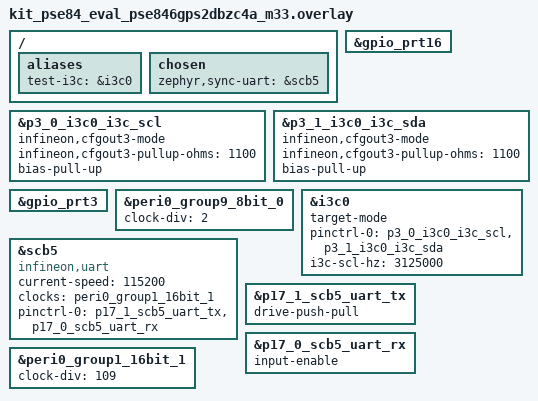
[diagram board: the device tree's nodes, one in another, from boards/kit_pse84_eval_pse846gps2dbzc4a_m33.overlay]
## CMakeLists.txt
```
# SPDX-FileCopyrightText: Copyright (c) 2026 Infineon Technologies AG,
# SPDX-FileCopyrightText: or an affiliate of Infineon Technologies AG. All rights reserved.
#
# SPDX-License-Identifier: Apache-2.0

cmake_minimum_required(VERSION 3.20.0)
find_package(Zephyr REQUIRED HINTS $ENV{ZEPHYR_BASE})
project(target_driven_target)

file(GLOB app_sources CONFIGURE_DEPENDS src/*.c)
target_sources(app PRIVATE ${app_sources})

target_include_directories(app PRIVATE ${CMAKE_CURRENT_SOURCE_DIR}/../../common)
```

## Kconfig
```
# SPDX-FileCopyrightText: Copyright (c) 2026 Infineon Technologies AG,
# SPDX-FileCopyrightText: or an affiliate of Infineon Technologies AG. All rights reserved.
#
# SPDX-License-Identifier: Apache-2.0

mainmenu "I3C loopback test (target)"

source "Kconfig.zephyr"

menu "I3C loopback target bench options"

config I3C_DUAL_BOARD_LOOPBACK_TARGET_VENDOR_WRAPPER_GATE
	bool "Re-open vendor clock-gate register during SOFT_RST"
	help
	  Some DW I3C IP integrations gate the protocol clock through a
	  vendor wrapper register that must be re-opened before SOFT_RST
	  can self-clear.  Enable this option for those integrations and
	  set the wrapper register offset and write value below.

if I3C_DUAL_BOARD_LOOPBACK_TARGET_VENDOR_WRAPPER_GATE

config I3C_DUAL_BOARD_LOOPBACK_TARGET_WRAPPER_GATE_OFFSET
	hex "Vendor wrapper-gate register offset from controller base"
	default 0x400

config I3C_DUAL_BOARD_LOOPBACK_TARGET_WRAPPER_GATE_VALUE
	hex "Value to write to the wrapper-gate register"
	default 0x80000000

endif

config I3C_DUAL_BOARD_LOOPBACK_TARGET_SOFT_RST_CLEARS_DEVICE_ADDR
	bool "DW SOFT_RST already clears DEVICE_ADDR (default true)"
	default y
	help
	  On most DW I3C variants, SOFT_RST also clears the DEVICE_ADDR
	  register.  Disable this option for variants where the stale
	  dynamic address from a previous ENTDAA round survives SOFT_RST
	  — the target side will then explicitly zero DEVICE_ADDR after
	  the reset to avoid the target believing it already has a DA
	  during the next enumeration round.

config I3C_DUAL_BOARD_LOOPBACK_TARGET_ALT_ADDR
	hex "Spare dynamic address for the address-change cases"
	default 0x40
	range 0x08 0x7d
	help
	  Address the SETNEWDA and SETDASA cases move the target to, and
	  then prove carries traffic.  Nothing else on the bus may answer
	  to it: it has to differ from the target's own static address,
	  from the controller's primary-controller-da, and from any
	  target sharing the bus.  Override it per board where the
	  default is taken.
endmenu
```

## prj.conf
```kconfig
# SPDX-FileCopyrightText: Copyright (c) 2026 Infineon Technologies AG,
# SPDX-FileCopyrightText: or an affiliate of Infineon Technologies AG. All rights reserved.
#
# SPDX-License-Identifier: Apache-2.0
#
# Target app for the target_driven two-board test pair.  Unlike the
# controller_driven pair, this side runs the ZTEST suite: it asserts on
# target-side state the controller cannot observe.

CONFIG_ZTEST=y
CONFIG_ZTEST_STACK_SIZE=4096

CONFIG_PRINTK_SYNC=y
CONFIG_FAULT_DUMP=2
CONFIG_LOG=y
CONFIG_ASSERT=y

# I3C: target-only build so the controller paths cannot mask a target bug
CONFIG_I3C=y
CONFIG_I3C_TARGET_ROLE_ONLY=y
CONFIG_I3C_USE_IBI=y

# Sync UART (poll-mode only - do not enable CONFIG_UART_INTERRUPT_DRIVEN;
# on this bench the UART IRQ handler races poll_in/poll_out and wedges
# subsequent I3C traffic.)
CONFIG_SERIAL=y

# Misc
CONFIG_PINCTRL_KEEP_SLEEP_STATE=y
CONFIG_HEAP_MEM_POOL_SIZE=4096
CONFIG_MAIN_STACK_SIZE=4096
CONFIG_CLOCK_CONTROL=y
```

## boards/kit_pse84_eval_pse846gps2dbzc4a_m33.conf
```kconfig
# SPDX-FileCopyrightText: Copyright (c) 2026 Infineon Technologies AG,
# SPDX-FileCopyrightText: or an affiliate of Infineon Technologies AG. All rights reserved.
#
# SPDX-License-Identifier: Apache-2.0
#
# Bench configuration for KIT_PSE84_EVAL (PSE846GPS2DBZC4A, M33 core).
#
# The Infineon DW I3C wrapper on PSE84 silicon has an integration
# quirk: a vendor wrapper-gate register at base+0x400 must be
# re-opened for SOFT_RST to self-clear, because the protocol clock
# is gated by it.
CONFIG_I3C_DUAL_BOARD_LOOPBACK_TARGET_VENDOR_WRAPPER_GATE=y
CONFIG_I3C_DUAL_BOARD_LOOPBACK_TARGET_WRAPPER_GATE_OFFSET=0x400
CONFIG_I3C_DUAL_BOARD_LOOPBACK_TARGET_WRAPPER_GATE_VALUE=0x80000000

# On PSE84 silicon, SOFT_RST does NOT clear DEVICE_ADDR - the stale
# dynamic address from the previous ENTDAA round survives and breaks
# re-enumeration.  Disable so the target zeros DEVICE_ADDR explicitly.
CONFIG_I3C_DUAL_BOARD_LOOPBACK_TARGET_SOFT_RST_CLEARS_DEVICE_ADDR=n

# Spare address for the SETNEWDA/SETDASA cases: free on this bench,
# below the on-board sensors and above the controller's own DA.
CONFIG_I3C_DUAL_BOARD_LOOPBACK_TARGET_ALT_ADDR=0x40
```

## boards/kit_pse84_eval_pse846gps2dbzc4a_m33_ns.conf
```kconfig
# SPDX-FileCopyrightText: Copyright (c) 2026 Infineon Technologies AG,
# SPDX-FileCopyrightText: or an affiliate of Infineon Technologies AG. All rights reserved.
#
# SPDX-License-Identifier: Apache-2.0
#
# Bench configuration for KIT_PSE84_EVAL (PSE846GPS2DBZC4A, M33 non-secure
# core, TF-M).
#
# The Infineon DW I3C wrapper on PSE84 silicon has an integration
# quirk: a vendor wrapper-gate register at base+0x400 must be
# re-opened for SOFT_RST to self-clear, because the protocol clock
# is gated by it.
CONFIG_I3C_DUAL_BOARD_LOOPBACK_TARGET_VENDOR_WRAPPER_GATE=y
CONFIG_I3C_DUAL_BOARD_LOOPBACK_TARGET_WRAPPER_GATE_OFFSET=0x400
CONFIG_I3C_DUAL_BOARD_LOOPBACK_TARGET_WRAPPER_GATE_VALUE=0x80000000

# On PSE84 silicon, SOFT_RST does NOT clear DEVICE_ADDR - the stale
# dynamic address from the previous ENTDAA round survives and breaks
# re-enumeration.  Disable so the target zeros DEVICE_ADDR explicitly.
CONFIG_I3C_DUAL_BOARD_LOOPBACK_TARGET_SOFT_RST_CLEARS_DEVICE_ADDR=n

# Spare address for the SETNEWDA/SETDASA cases: free on this bench,
# below the on-board sensors and above the controller's own DA.
CONFIG_I3C_DUAL_BOARD_LOOPBACK_TARGET_ALT_ADDR=0x40
```

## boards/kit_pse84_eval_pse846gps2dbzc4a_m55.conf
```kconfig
# SPDX-FileCopyrightText: Copyright (c) 2026 Infineon Technologies AG,
# SPDX-FileCopyrightText: or an affiliate of Infineon Technologies AG. All rights reserved.
#
# SPDX-License-Identifier: Apache-2.0
#
# Bench configuration for KIT_PSE84_EVAL (PSE846GPS2DBZC4A, M55 core).
#
# The Infineon DW I3C wrapper on PSE84 silicon has an integration
# quirk: a vendor wrapper-gate register at base+0x400 must be
# re-opened for SOFT_RST to self-clear, because the protocol clock
# is gated by it.
CONFIG_I3C_DUAL_BOARD_LOOPBACK_TARGET_VENDOR_WRAPPER_GATE=y
CONFIG_I3C_DUAL_BOARD_LOOPBACK_TARGET_WRAPPER_GATE_OFFSET=0x400
CONFIG_I3C_DUAL_BOARD_LOOPBACK_TARGET_WRAPPER_GATE_VALUE=0x80000000

# On PSE84 silicon, SOFT_RST does NOT clear DEVICE_ADDR - the stale
# dynamic address from the previous ENTDAA round survives and breaks
# re-enumeration.  Disable so the target zeros DEVICE_ADDR explicitly.
CONFIG_I3C_DUAL_BOARD_LOOPBACK_TARGET_SOFT_RST_CLEARS_DEVICE_ADDR=n

# Spare address for the SETNEWDA/SETDASA cases: free on this bench,
# below the on-board sensors and above the controller's own DA.
CONFIG_I3C_DUAL_BOARD_LOOPBACK_TARGET_ALT_ADDR=0x40
```

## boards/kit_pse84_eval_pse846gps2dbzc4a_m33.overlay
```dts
/*
 * SPDX-FileCopyrightText: Copyright (c) 2026 Infineon Technologies AG,
 * SPDX-FileCopyrightText: or an affiliate of Infineon Technologies AG. All rights reserved.
 *
 * SPDX-License-Identifier: Apache-2.0
 *
 * Board overlay for the dual_board_loopback TARGET (Board B) on
 * KIT_PSE84_EVAL (M33 core).
 *
 * Wiring:
 *   B.I3C0_SCL - shared with A.I3C0_SCL    (P3.0)
 *   B.I3C0_SDA - shared with A.I3C0_SDA    (P3.1)
 *   B.SCB5 RX/TX - crossed with A.SCB5 TX/RX           (P17.0/P17.1)
 *   B.GREEN LED   - LA channel 2 (target-IP-saw-address marker, P16.6)
 */

#include <zephyr/dt-bindings/gpio/gpio.h>

/ {
	aliases {
		test-i3c = &i3c0;
	};

	chosen {
		zephyr,sync-uart = &scb5;
	};
};

&gpio_prt16 {
	status = "okay";
};

&p3_0_i3c0_i3c_scl {
	infineon,cfgout3-mode;
	infineon,cfgout3-pullup-ohms = <1100>;
	bias-pull-up;
};

&p3_1_i3c0_i3c_sda {
	infineon,cfgout3-mode;
	infineon,cfgout3-pullup-ohms = <1100>;
	bias-pull-up;
};

&gpio_prt3 {
	status = "okay";
};

/* Match the controller overlay: the target samples SCL with this clock. */
&peri0_group9_8bit_0 {
	status = "okay";
	clock-div = <2>;
};

&i3c0 {
	status = "okay";
	target-mode;
	pinctrl-0 = <&p3_0_i3c0_i3c_scl &p3_1_i3c0_i3c_sda>;
	pinctrl-names = "default";
	i3c-scl-hz = <3125000>;

	/* Target PID/BCR/DCR are set at runtime; see common/test_identity.h. */
};

scb5_sync_uart: &scb5 {
	compatible = "infineon,uart";
	status = "okay";
	current-speed = <115200>;
	clocks = <&peri0_group1_16bit_1>;
	pinctrl-0 = <&p17_1_scb5_uart_tx &p17_0_scb5_uart_rx>;
	pinctrl-names = "default";
};

&p17_1_scb5_uart_tx {
	drive-push-pull;
};

&p17_0_scb5_uart_rx {
	input-enable;
};

&peri0_group1_16bit_1 {
	status = "okay";
	clock-div = <109>;
};
```

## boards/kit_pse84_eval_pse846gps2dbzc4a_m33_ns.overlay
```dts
/*
 * SPDX-FileCopyrightText: Copyright (c) 2026 Infineon Technologies AG,
 * SPDX-FileCopyrightText: or an affiliate of Infineon Technologies AG. All rights reserved.
 *
 * SPDX-License-Identifier: Apache-2.0
 *
 * Board overlay for the dual_board_loopback TARGET (Board B) on
 * KIT_PSE84_EVAL (M33 non-secure core, TF-M).
 *
 * Wiring:
 *   B.I3C0_SCL - shared with A.I3C0_SCL    (P3.0)
 *   B.I3C0_SDA - shared with A.I3C0_SDA    (P3.1)
 *   B.SCB5 RX/TX - crossed with A.SCB5 TX/RX           (P17.0/P17.1)
 *   B.GREEN LED   - LA channel 2 (target-IP-saw-address marker, P16.6)
 */

#include <zephyr/dt-bindings/gpio/gpio.h>

/ {
	aliases {
		test-i3c = &i3c0;
	};

	chosen {
		zephyr,sync-uart = &scb5;
	};
};

&gpio_prt16 {
	status = "okay";
};

&p3_0_i3c0_i3c_scl {
	infineon,cfgout3-mode;
	infineon,cfgout3-pullup-ohms = <1100>;
	bias-pull-up;
};

&p3_1_i3c0_i3c_sda {
	infineon,cfgout3-mode;
	infineon,cfgout3-pullup-ohms = <1100>;
	bias-pull-up;
};

&gpio_prt3 {
	status = "okay";
};

/* Match the controller overlay: the target samples SCL with this clock. */
&peri0_group9_8bit_0 {
	status = "okay";
	clock-div = <2>;
};

&i3c0 {
	status = "okay";
	target-mode;
	pinctrl-0 = <&p3_0_i3c0_i3c_scl &p3_1_i3c0_i3c_sda>;
	pinctrl-names = "default";
	i3c-scl-hz = <3125000>;

	/* Target PID/BCR/DCR are set at runtime; see common/test_identity.h. */
};

scb5_sync_uart: &scb5 {
	compatible = "infineon,uart";
	status = "okay";
	current-speed = <115200>;
	clocks = <&peri0_group1_16bit_1>;
	pinctrl-0 = <&p17_1_scb5_uart_tx &p17_0_scb5_uart_rx>;
	pinctrl-names = "default";
};

&p17_1_scb5_uart_tx {
	drive-push-pull;
};

&p17_0_scb5_uart_rx {
	input-enable;
};

&peri0_group1_16bit_1 {
	status = "okay";
	clock-div = <109>;
};
```

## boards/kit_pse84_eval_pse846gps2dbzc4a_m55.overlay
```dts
/*
 * SPDX-FileCopyrightText: Copyright (c) 2026 Infineon Technologies AG,
 * SPDX-FileCopyrightText: or an affiliate of Infineon Technologies AG. All rights reserved.
 *
 * SPDX-License-Identifier: Apache-2.0
 *
 * Board overlay for the dual_board_loopback TARGET (Board B) on
 * KIT_PSE84_EVAL (M55 core).
 *
 * Wiring:
 *   B.I3C0_SCL - shared with A.I3C0_SCL    (P3.0)
 *   B.I3C0_SDA - shared with A.I3C0_SDA    (P3.1)
 *   B.SCB5 RX/TX - crossed with A.SCB5 TX/RX           (P17.0/P17.1)
 *   B.GREEN LED   - LA channel 2 (target-IP-saw-address marker, P16.6)
 */

#include <zephyr/dt-bindings/gpio/gpio.h>

/ {
	aliases {
		test-i3c = &i3c0;
	};

	chosen {
		zephyr,sync-uart = &scb5;
	};
};

&gpio_prt16 {
	status = "okay";
};

&p3_0_i3c0_i3c_scl {
	infineon,cfgout3-mode;
	infineon,cfgout3-pullup-ohms = <1100>;
	bias-pull-up;
};

&p3_1_i3c0_i3c_sda {
	infineon,cfgout3-mode;
	infineon,cfgout3-pullup-ohms = <1100>;
	bias-pull-up;
};

&gpio_prt3 {
	status = "okay";
};

/* Match the controller overlay: the target samples SCL with this clock. */
&peri0_group9_8bit_0 {
	status = "okay";
	clock-div = <2>;
};

&i3c0 {
	status = "okay";
	target-mode;
	pinctrl-0 = <&p3_0_i3c0_i3c_scl &p3_1_i3c0_i3c_sda>;
	pinctrl-names = "default";
	i3c-scl-hz = <3125000>;

	/* Target PID/BCR/DCR are set at runtime; see common/test_identity.h. */
};

scb5_sync_uart: &scb5 {
	compatible = "infineon,uart";
	status = "okay";
	current-speed = <115200>;
	clocks = <&peri0_group1_16bit_1>;
	pinctrl-0 = <&p17_1_scb5_uart_tx &p17_0_scb5_uart_rx>;
	pinctrl-names = "default";
};

&p17_1_scb5_uart_tx {
	drive-push-pull;
};

&p17_0_scb5_uart_rx {
	input-enable;
};

&peri0_group1_16bit_1 {
	status = "okay";
	clock-div = <109>;
};
```

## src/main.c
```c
/*
 * SPDX-FileCopyrightText: Copyright (c) 2026 Infineon Technologies AG,
 * SPDX-FileCopyrightText: or an affiliate of Infineon Technologies AG. All rights reserved.
 *
 * SPDX-License-Identifier: Apache-2.0
 *
 * Target-side fixture for the target_driven two-board test pair.
 *
 * Board A is the I3C controller and Board B (this app) is the I3C target.
 * Board B owns the ZTEST suite here.  This file holds the DT handles,
 * the I3C target callbacks and their event log, the sync-UART request
 * helpers, and the ZTEST_SUITE registration.  Per-test ZTEST() bodies
 * live in the other src/test_*.c files.
 *
 * The helpers come in four families, declared with their per-function
 * documentation in test_common.h:
 *
 *   event_*   - the callback event log.  The I3C target callbacks append to
 *               it, and a case asserts on what landed: how many bytes, in
 *               what order, and which callbacks fired.  This is the suite's
 *               only view of target-side behaviour, since the APIs expose no
 *               other way to observe it.
 *   ctrl_*    - stimulus.  Each one asks Board A over the sync UART to put
 *               something on the bus (a write, a read, a CCC, an abort, a
 *               re-enumeration) and reports both whether A answered and A's
 *               own return code, so a case can tell a harness failure from a
 *               bus failure.
 *   target_*  - this target's own state: the callback table bound to the
 *               driver, buffer-mode entry and exit, staged read data, and the
 *               configuration applied at suite setup.
 *   suite_*   - ZTEST_SUITE setup and per-test hooks.
 */

#include "test_common.h"
#include "test_identity.h"

#include <zephyr/device.h>
#include <zephyr/devicetree.h>
#include <zephyr/drivers/i3c.h>
#include <zephyr/drivers/i3c/target_device.h>
#include <zephyr/drivers/uart.h>
#include <zephyr/init.h>
#include <zephyr/kernel.h>
#include <zephyr/logging/log.h>
#include <zephyr/sys/atomic.h>
#include <zephyr/sys/printk.h>
#include <zephyr/ztest.h>
#include <string.h>

LOG_MODULE_REGISTER(target_driven_tgt, LOG_LEVEL_INF);

static int early_boot_marker(void)
{
	printk("\n\n*** TD-TARGET BUILD " __DATE__ " " __TIME__ " ***\n\n");
	return 0;
}
SYS_INIT(early_boot_marker, APPLICATION, 0);

const struct device *const i3c_dev = DEVICE_DT_GET(DT_ALIAS(test_i3c));
const struct device *const sync_uart = DEVICE_DT_GET(DT_CHOSEN(zephyr_sync_uart));

uint8_t target_da;

/*
 * --------------------------------------------------------------------------
 * Callback event log
 * --------------------------------------------------------------------------
 */
static struct event_entry ev_log[EVENT_LOG_MAX];
static atomic_t ev_total;

void event_record(enum event_kind kind, uint8_t val)
{
	atomic_val_t idx = atomic_inc(&ev_total);

	if (idx < (atomic_val_t)EVENT_LOG_MAX) {
		ev_log[idx].kind = (uint8_t)kind;
		ev_log[idx].val = val;
	}
}

void event_reset(void)
{
	atomic_set(&ev_total, 0);
}

size_t event_total(void)
{
	return (size_t)atomic_get(&ev_total);
}

size_t event_stored(void)
{
	return MIN(event_total(), (size_t)EVENT_LOG_MAX);
}

const struct event_entry *event_at(size_t idx)
{
	if (idx >= event_stored()) {
		return NULL;
	}
	return &ev_log[idx];
}

size_t event_count(enum event_kind kind)
{
	const size_t n = event_stored();
	size_t count = 0;

	for (size_t i = 0; i < n; i++) {
		if (ev_log[i].kind == (uint8_t)kind) {
			count++;
		}
	}
	return count;
}

size_t event_payload(uint8_t *out, size_t out_max)
{
	const size_t n = event_stored();
	size_t count = 0;

	for (size_t i = 0; (i < n) && (count < out_max); i++) {
		if (ev_log[i].kind == (uint8_t)EVENT_WRITE_BYTE) {
			out[count] = ev_log[i].val;
			count++;
		}
	}
	return count;
}

int event_wait_count(enum event_kind kind, size_t want, k_timeout_t timeout)
{
	const k_timepoint_t deadline = sys_timepoint_calc(timeout);
	const size_t total_before = event_total();

	while (event_count(kind) < want) {
		if (sys_timepoint_expired(deadline)) {
			if (event_total() == total_before) {
				return -EAGAIN;
			}
			return (event_count(kind) == 0U) ? -EPROTO : -EMSGSIZE;
		}
		k_msleep(1);
	}
	return 0;
}

const char *event_kind_name(enum event_kind kind)
{
	/* Indexed rather than positional, so reordering enum event_kind cannot
	 * silently relabel the log.
	 */
	static const char *const names[] = {
		[EVENT_WRITE_REQUESTED] = "write_requested",
		[EVENT_WRITE_BYTE] = "write_byte",
		[EVENT_READ_REQUESTED] = "read_requested",
		[EVENT_READ_PROCESSED] = "read_processed",
		[EVENT_STOP] = "stop",
		[EVENT_BUF_WRITE] = "buf_write",
		[EVENT_BUF_READ] = "buf_read",
	};

	BUILD_ASSERT(ARRAY_SIZE(names) == EVENT_KIND_COUNT,
		     "enum event_kind gained a kind with no name in names[]");

	if (((size_t)kind >= ARRAY_SIZE(names)) || (names[kind] == NULL)) {
		return "?";
	}
	return names[kind];
}

void event_dump(void)
{
	const size_t n = event_stored();

	printk("[ev] total=%zu stored=%zu\n", event_total(), n);
	for (size_t i = 0; i < n; i++) {
		printk("[ev] %2zu %-16s 0x%02x\n", i, event_kind_name(ev_log[i].kind),
		       ev_log[i].val);
	}
}

void ctrl_assert_bus_outcome(const char *what, int a_rc)
{
	switch (a_rc) {
	case -EINVAL:
	case -ENOTSUP:
	case -EACCES:
	case -EADDRNOTAVAIL:
		zassert_unreachable("%s: Board A rejected the transfer locally (%d), so it "
				    "never reached the bus and the target was never exercised",
				    what, a_rc);
		break;
	case -EAGAIN:
		/* dw_i3c_xfers() presets -EAGAIN and keeps it when the response
		 * interrupt never arrives, so nothing was learned about the bus.
		 */
		zassert_unreachable("%s: the transfer timed out with no response (%d); the "
				    "checks below cannot distinguish that from success",
				    what, a_rc);
		break;
	default:
		break;
	}
}

/*
 * --------------------------------------------------------------------------
 * I3C target callbacks
 * --------------------------------------------------------------------------
 */
static int tgt_write_requested(struct i3c_target_config *cfg)
{
	ARG_UNUSED(cfg);
	event_record(EVENT_WRITE_REQUESTED, 0);
	return 0;
}

static int tgt_write_received(struct i3c_target_config *cfg, uint8_t val)
{
	ARG_UNUSED(cfg);
	event_record(EVENT_WRITE_BYTE, val);
	return 0;
}

static int tgt_read_requested(struct i3c_target_config *cfg, uint8_t *val)
{
	ARG_UNUSED(cfg);
	/* Per DW databook 6.1.9 (INTR_STATUS bit 11) the DW IP raises this only
	 * when the command queue is empty, and passes val == NULL: it is an
	 * underrun notification, not a request for data.
	 */
	if (val != NULL) {
		*val = 0;
	}
	event_record(EVENT_READ_REQUESTED, 0);
	return 0;
}

static int tgt_read_processed(struct i3c_target_config *cfg, uint8_t *val)
{
	ARG_UNUSED(cfg);
	if (val != NULL) {
		*val = 0;
	}
	event_record(EVENT_READ_PROCESSED, 0);
	return 0;
}

static int tgt_stop(struct i3c_target_config *cfg)
{
	ARG_UNUSED(cfg);
	event_record(EVENT_STOP, 0);
	return 0;
}

uint8_t target_buf_rx[TARGET_BUF_MAX];
size_t target_buf_rx_len;

void target_buf_reset(void)
{
	target_buf_rx_len = 0;
	memset(target_buf_rx, 0, sizeof(target_buf_rx));
}

#ifdef CONFIG_I3C_TARGET_BUFFER_MODE
static void tgt_buf_write_received(struct i3c_target_config *cfg, uint8_t *ptr, uint32_t len)
{
	ARG_UNUSED(cfg);

	target_buf_rx_len = MIN((size_t)len, sizeof(target_buf_rx));
	if (ptr != NULL) {
		memcpy(target_buf_rx, ptr, target_buf_rx_len);
	}
	/* val carries the length the driver reported, not the length retained. */
	event_record(EVENT_BUF_WRITE, (uint8_t)len);
}

static int tgt_buf_read_requested(struct i3c_target_config *cfg, uint8_t **ptr, uint32_t *len,
				  uint8_t *hdr_mode)
{
	ARG_UNUSED(cfg);
	ARG_UNUSED(ptr);
	ARG_UNUSED(len);
	ARG_UNUSED(hdr_mode);

	/* Underrun report, not a request for data: an I3C target cannot stall,
	 * so read data is pre-staged with i3c_target_tx_write() instead.
	 */
	event_record(EVENT_BUF_READ, 0);
	return 0;
}
#endif /* CONFIG_I3C_TARGET_BUFFER_MODE */

const struct i3c_target_callbacks target_callbacks = {
	.write_requested_cb = tgt_write_requested,
	.write_received_cb = tgt_write_received,
	.read_requested_cb = tgt_read_requested,
	.read_processed_cb = tgt_read_processed,
	.stop_cb = tgt_stop,
};

/* i3c_target_unregister() rejects a config the driver is not holding, so the
 * restore in suite_before_each() has to name the live one.
 */
static struct i3c_target_config *bound_cfg;

int target_bind(struct i3c_target_config *cfg)
{
	int rc;

	if (bound_cfg != NULL) {
		rc = i3c_target_unregister(i3c_dev, bound_cfg);
		if ((rc != 0) && (rc != -ENOSYS)) {
			return rc;
		}
		bound_cfg = NULL;
	}

	rc = i3c_target_register(i3c_dev, cfg);
	if ((rc != 0) && (rc != -ENOSYS)) {
		return rc;
	}

	bound_cfg = cfg;
	return 0;
}

#ifdef CONFIG_I3C_TARGET_BUFFER_MODE
/*
 * The driver picks the delivery path from the registered table, so this one
 * deliberately omits the per-byte callbacks: registering it is what puts the
 * target into buffer mode.
 */
static const struct i3c_target_callbacks target_buf_callbacks = {
	.stop_cb = tgt_stop,
	.buf_write_received_cb = tgt_buf_write_received,
	.buf_read_requested_cb = tgt_buf_read_requested,
};

static struct i3c_target_config target_buf_cfg = {
	.callbacks = &target_buf_callbacks,
};

/* Both delivery paths registered at once, so a case can observe which one the
 * driver picks.
 */
static const struct i3c_target_callbacks target_both_callbacks = {
	.write_received_cb = tgt_write_received,
	.stop_cb = tgt_stop,
	.buf_write_received_cb = tgt_buf_write_received,
	.buf_read_requested_cb = tgt_buf_read_requested,
};

static struct i3c_target_config target_both_cfg = {
	.callbacks = &target_both_callbacks,
};

/* Tiny binding helpers - for readability */
int target_buf_mode_enter(void)
{
	return target_bind(&target_buf_cfg);
}

int target_buf_mode_exit(void)
{
	return target_bind(&target_cfg);
}

int target_both_mode_enter(void)
{
	return target_bind(&target_both_cfg);
}

int target_both_mode_exit(void)
{
	return target_bind(&target_cfg);
}
#endif /* CONFIG_I3C_TARGET_BUFFER_MODE */

struct i3c_target_config target_cfg = {
	.callbacks = &target_callbacks,
};

/*
 * --------------------------------------------------------------------------
 * Stimulus requests to Board A
 * --------------------------------------------------------------------------
 */
#define REPLY_TIMEOUT K_SECONDS(3)

int ctrl_write(const uint8_t *buf, size_t len, int *rc_out)
{
	char hex[(TARGET_BUF_MAX * 2U) + 1U];
	char line[SYNC_LINE_MAX];
	int rc;

	if (bytes_to_hex(buf, len, hex, sizeof(hex)) != 0) {
		return -ENOSPC;
	}

	sync_drain(sync_uart);
	sync_send(sync_uart, "DO_WRITE %s", hex);

	rc = sync_expect_line(sync_uart, "DONE", line, sizeof(line), REPLY_TIMEOUT);
	if (rc != 0) {
		return rc;
	}
	if (sscanf(line, "DONE write rc=%d", rc_out) != 1) {
		return -EPROTO;
	}
	return 0;
}

int ctrl_burst_begin(unsigned int count, size_t len, uint8_t base)
{
	char line[SYNC_LINE_MAX];

	sync_drain(sync_uart);
	sync_send(sync_uart, "BURST_WRITE %u %zu %u", count, len, base);

	return sync_expect_line(sync_uart, "ARMED", line, sizeof(line), REPLY_TIMEOUT);
}

int ctrl_burst_end(unsigned int *sent_out, int *rc_out)
{
	char line[SYNC_LINE_MAX];
	int rc = sync_expect_line(sync_uart, "DONE", line, sizeof(line), REPLY_TIMEOUT);

	if (rc != 0) {
		return rc;
	}
	if (sscanf(line, "DONE burst rc=%d sent=%u", rc_out, sent_out) != 2) {
		return -EPROTO;
	}
	return 0;
}

int ctrl_read(size_t len, uint8_t *out, size_t out_max, int *rc_out)
{
	char line[SYNC_LINE_MAX];
	char hex[(TARGET_BUF_MAX * 2U) + 1U];
	int rc;
	int n;

	sync_drain(sync_uart);
	sync_send(sync_uart, "DO_READ %zu", len);

	rc = sync_expect_line(sync_uart, "DONE", line, sizeof(line), REPLY_TIMEOUT);
	if (rc != 0) {
		return rc;
	}

	hex[0] = '\0';
	if (sscanf(line, "DONE read rc=%d %64s", rc_out, hex) < 1) {
		return -EPROTO;
	}

	n = hex_to_bytes(hex, out, out_max);
	return (n < 0) ? n : 0;
}

int ctrl_write_addr(uint8_t addr, const uint8_t *buf, size_t len, int *rc_out)
{
	char hex[(TARGET_BUF_MAX * 2U) + 1U];
	char line[SYNC_LINE_MAX];
	int rc;

	if (bytes_to_hex(buf, len, hex, sizeof(hex)) != 0) {
		return -ENOSPC;
	}

	sync_drain(sync_uart);
	sync_send(sync_uart, "DO_WRITE_ADDR 0x%02x %s", addr, hex);

	rc = sync_expect_line(sync_uart, "DONE", line, sizeof(line), REPLY_TIMEOUT);
	if (rc != 0) {
		return rc;
	}
	if (sscanf(line, "DONE write_addr rc=%d", rc_out) != 1) {
		return -EPROTO;
	}
	return 0;
}

int ctrl_read_addr(uint8_t addr, size_t len, uint8_t *out, size_t out_max, int *rc_out)
{
	char line[SYNC_LINE_MAX];
	char hex[(TARGET_BUF_MAX * 2U) + 1U];
	int rc;
	int n;

	sync_drain(sync_uart);
	sync_send(sync_uart, "DO_READ_ADDR 0x%02x %zu", addr, len);

	rc = sync_expect_line(sync_uart, "DONE", line, sizeof(line), REPLY_TIMEOUT);
	if (rc != 0) {
		return rc;
	}

	hex[0] = '\0';
	if (sscanf(line, "DONE read_addr rc=%d %64s", rc_out, hex) < 1) {
		return -EPROTO;
	}

	n = hex_to_bytes(hex, out, out_max);
	return (n < 0) ? n : 0;
}

int ctrl_re_enum(int *rc_out)
{
	char line[SYNC_LINE_MAX];
	unsigned int da = 0;
	int rc;

	sync_drain(sync_uart);
	sync_send(sync_uart, "RE_ENUM");

	rc = sync_expect_line(sync_uart, "ENUM", line, sizeof(line), K_SECONDS(10));
	if (rc != 0) {
		return rc;
	}
	if (sscanf(line, "ENUM da=%x rc=%d", &da, rc_out) != 2) {
		return -EPROTO;
	}
	target_da = (uint8_t)da;
	return 0;
}

int ctrl_recover(int *rc_out)
{
	char line[SYNC_LINE_MAX];
	int rc;

	sync_drain(sync_uart);
	sync_send(sync_uart, "RECOVER");

	rc = sync_expect_line(sync_uart, "DONE", line, sizeof(line), REPLY_TIMEOUT);
	if (rc != 0) {
		return rc;
	}
	if (sscanf(line, "DONE recover rc=%d", rc_out) != 1) {
		return -EPROTO;
	}
	return 0;
}

int ctrl_write_abort(size_t len, uint32_t delay_us, size_t *sent_out, int *rc_out)
{
	char line[SYNC_LINE_MAX];
	unsigned int sent = 0;
	int rc;

	sync_drain(sync_uart);
	sync_send(sync_uart, "DO_WRITE_ABORT %u %u", (unsigned int)len, (unsigned int)delay_us);

	rc = sync_expect_line(sync_uart, "DONE", line, sizeof(line), REPLY_TIMEOUT);
	if (rc != 0) {
		return rc;
	}
	if (sscanf(line, "DONE write_abort rc=%d sent=%u", rc_out, &sent) != 2) {
		return -EPROTO;
	}
	if (sent_out != NULL) {
		*sent_out = sent;
	}
	return 0;
}

int ctrl_dump(struct ctrl_view *out)
{
	char line[SYNC_LINE_MAX];
	unsigned int da = 0;
	unsigned int bcr = 0;
	unsigned int dcr = 0;
	unsigned int pidhi = 0;
	unsigned int pidlo = 0;
	int rc;

	sync_drain(sync_uart);
	sync_send(sync_uart, "A_DUMP");

	rc = sync_expect_line(sync_uart, "ADUMP", line, sizeof(line), REPLY_TIMEOUT);
	if (rc != 0) {
		return rc;
	}
	if (sscanf(line, "ADUMP da=%x bcr=%x dcr=%x pidhi=%x pidlo=%x", &da, &bcr, &dcr, &pidhi,
		   &pidlo) != 5) {
		return -EPROTO;
	}

	out->da = (uint8_t)da;
	out->bcr = (uint8_t)bcr;
	out->dcr = (uint8_t)dcr;
	out->pid = ((uint64_t)pidhi << 32) | pidlo;
	return 0;
}

int ctrl_ccc(const char *args, int *rc_out, unsigned int *val_out)
{
	char line[SYNC_LINE_MAX];
	unsigned int val = 0;
	int rc;

	sync_drain(sync_uart);
	sync_send(sync_uart, "DO_CCC %s", args);

	/* RSTDAA and ENTDAA re-run enumeration on A, which outlasts the
	 * ordinary reply budget.
	 */
	rc = sync_expect_line(sync_uart, "DONE", line, sizeof(line), K_SECONDS(10));
	if (rc != 0) {
		return rc;
	}
	if (sscanf(line, "DONE ccc rc=%d val=%u", rc_out, &val) < 1) {
		return -EPROTO;
	}
	if (val_out != NULL) {
		*val_out = val;
	}
	return 0;
}

int ctrl_raw_ccc(uint8_t id, bool read, size_t len, int *rc_out, int *err_out)
{
	char line[SYNC_LINE_MAX];
	int err = 0;
	int rc;

	sync_drain(sync_uart);
	sync_send(sync_uart, "DO_RAW_CCC 0x%02x %u %zu", id, read ? 1U : 0U, len);

	rc = sync_expect_line(sync_uart, "DONE", line, sizeof(line), REPLY_TIMEOUT);
	if (rc != 0) {
		return rc;
	}
	if (sscanf(line, "DONE raw_ccc rc=%d err=%d", rc_out, &err) < 1) {
		return -EPROTO;
	}
	if (err_out != NULL) {
		*err_out = err;
	}
	return 0;
}

int ctrl_xfer(const uint8_t *buf, size_t len, size_t want, uint8_t *out, size_t out_max,
	       int *rc_out)
{
	char hex[(TARGET_BUF_MAX * 2U) + 1U];
	char line[SYNC_LINE_MAX];
	int rc;
	int n;

	if (bytes_to_hex(buf, len, hex, sizeof(hex)) != 0) {
		return -ENOSPC;
	}

	sync_drain(sync_uart);
	sync_send(sync_uart, "DO_XFER %s %zu", hex, want);

	rc = sync_expect_line(sync_uart, "DONE", line, sizeof(line), REPLY_TIMEOUT);
	if (rc != 0) {
		return rc;
	}

	hex[0] = '\0';
	if (sscanf(line, "DONE xfer rc=%d %64s", rc_out, hex) < 1) {
		return -EPROTO;
	}

	n = hex_to_bytes(hex, out, out_max);
	return (n < 0) ? n : 0;
}

int ctrl_round_trip(uint8_t seed, size_t len)
{
	uint8_t pattern[TARGET_BUF_MAX];
	uint8_t got[TARGET_BUF_MAX];
	size_t n;
	int a_rc = -1;
	int rc;

	if ((len == 0U) || (len > sizeof(pattern))) {
		return -EINVAL;
	}

	event_reset();
	fill_pattern(pattern, len, seed);

	rc = ctrl_write(pattern, len, &a_rc);
	if (rc != 0) {
		return rc;
	}
	if (a_rc != 0) {
		return a_rc;
	}

	rc = event_wait_count(EVENT_WRITE_BYTE, len, CB_SETTLE);
	if (rc != 0) {
		return rc;
	}

	n = event_payload(got, sizeof(got));
	if (n != len) {
		return -EMSGSIZE;
	}
	for (size_t i = 0; i < len; i++) {
		if (got[i] != pattern[i]) {
			return -EBADMSG;
		}
	}

	return 0;
}

int ctrl_set_ibi(bool enable, int *rc_out)
{
	char line[SYNC_LINE_MAX];
	int rc;

	sync_drain(sync_uart);
	sync_send(sync_uart, "SET_IBI %s", enable ? "on" : "off");

	rc = sync_expect_line(sync_uart, "DONE", line, sizeof(line), REPLY_TIMEOUT);
	if (rc != 0) {
		return rc;
	}
	if (sscanf(line, "DONE ibi rc=%d", rc_out) != 1) {
		return -EPROTO;
	}
	return 0;
}

int ctrl_expect_ibi(uint32_t timeout_ms, uint8_t *out, size_t out_max, size_t *len_out)
{
	char hex[(TARGET_BUF_MAX * 2U) + 1U];
	char line[SYNC_LINE_MAX];
	k_timepoint_t deadline;
	unsigned int len = 0;
	int n;

	*len_out = 0;

	sync_drain(sync_uart);
	sync_send(sync_uart, "EXPECT_IBI %u", timeout_ms);

	/* Two replies are both valid answers, so this cannot use
	 * sync_expect_line(); Board A blocks for the whole window first.
	 */
	deadline = sys_timepoint_calc(K_MSEC(timeout_ms + 2000U));
	while (1) {
		if (sys_timepoint_expired(deadline)) {
			return -ETIMEDOUT;
		}
		n = sync_recv_line(sync_uart, line, sizeof(line),
				   sys_timepoint_timeout(deadline));
		if (n < 0) {
			return n;
		}
		if (strncmp(line, "NO_IBI", 6) == 0) {
			return -EAGAIN;
		}
		if (strncmp(line, "GOT_IBI", 7) == 0) {
			break;
		}
	}

	hex[0] = '\0';
	if (sscanf(line, "GOT_IBI len=%u %64s", &len, hex) < 1) {
		return -EPROTO;
	}

	n = hex_to_bytes(hex, out, out_max);
	if (n < 0) {
		return n;
	}
	*len_out = (size_t)len;
	return 0;
}

int ctrl_set_hj(bool enable, int *rc_out)
{
	char line[SYNC_LINE_MAX];
	int rc;

	sync_drain(sync_uart);
	sync_send(sync_uart, "SET_HJ %s", enable ? "on" : "off");

	rc = sync_expect_line(sync_uart, "DONE", line, sizeof(line), REPLY_TIMEOUT);
	if (rc != 0) {
		return rc;
	}
	if (sscanf(line, "DONE hj rc=%d", rc_out) != 1) {
		return -EPROTO;
	}
	return 0;
}

int ctrl_expect_hj(uint32_t timeout_ms, unsigned int *da_out)
{
	char line[SYNC_LINE_MAX];
	k_timepoint_t deadline;
	int n;

	*da_out = 0;

	sync_drain(sync_uart);
	sync_send(sync_uart, "EXPECT_HJ %u", timeout_ms);

	/* GOT_HJ and NO_HJ are both answers, so sync_expect_line() cannot be used. */
	deadline = sys_timepoint_calc(K_MSEC(timeout_ms + 5000U));
	while (1) {
		if (sys_timepoint_expired(deadline)) {
			return -ETIMEDOUT;
		}
		n = sync_recv_line(sync_uart, line, sizeof(line),
				   sys_timepoint_timeout(deadline));
		if (n < 0) {
			return n;
		}
		if (strncmp(line, "NO_HJ", 5) == 0) {
			return -EAGAIN;
		}
		if (strncmp(line, "GOT_HJ", 6) == 0) {
			break;
		}
	}

	if (sscanf(line, "GOT_HJ da=%u", da_out) != 1) {
		return -EPROTO;
	}
	return 0;
}

int target_stage_read(const uint8_t *buf, size_t len)
{
	int rc = i3c_target_tx_write(i3c_dev, (uint8_t *)buf, (uint16_t)len, 0);

	/* i3c_target_tx_write() returns the number of bytes accepted into the
	 * TX FIFO, not 0 on success. Normalize to the 0-or-negative convention
	 * the callers expect, and treat a short write as an error: the staged
	 * buffer would not match what the controller reads back.
	 */
	if (rc < 0) {
		return rc;
	}

	return (rc == (int)len) ? 0 : -ENOSPC;
}

/*
 * --------------------------------------------------------------------------
 * Suite plumbing
 * --------------------------------------------------------------------------
 */
int target_configure(void)
{
	struct i3c_config_target tcfg = {
		.enabled = true,
		.static_addr = TARGET_STATIC_ADDR,
		.pid = TARGET_PID,
		.pid_random = false,
		.bcr = TARGET_BCR,
		.dcr = TARGET_DCR,
		.max_read_len = TARGET_BUF_MAX,
		.max_write_len = TARGET_BUF_MAX,
		.supported_hdr = 0,
	};
	int rc;

	rc = i3c_configure(i3c_dev, I3C_CONFIG_TARGET, &tcfg);
	if (rc != 0) {
		return rc;
	}

	return target_bind(&target_cfg);
}

/*
 * Board A drives HELLO until we answer, then enumerates and announces
 * the result.  Answering only after target_configure() makes the
 * handshake the barrier that stops A enumerating a target that is not
 * yet listening.
 */
static int await_enumeration(k_timeout_t timeout)
{
	const k_timepoint_t deadline = sys_timepoint_calc(timeout);
	char line[SYNC_LINE_MAX];

	while (!sys_timepoint_expired(deadline)) {
		int rc;

		/*
		 * Greet repeatedly instead of waiting to be greeted: Board A
		 * only enumerates in response to a HELLO, so this is what lets
		 * either board boot first, or restart, without a stuck bus.
		 */
		sync_send(sync_uart, "HELLO");

		rc = sync_recv_line(sync_uart, line, sizeof(line), K_MSEC(500));
		if (rc < 0) {
			continue;
		}
		if (strncmp(line, "HELLO", 5) == 0) {
			continue;
		}
		if (strncmp(line, "ENUM", 4) == 0) {
			unsigned int da = 0;
			int a_rc = -1;

			if (sscanf(line, "ENUM da=%x rc=%d", &da, &a_rc) == 2) {
				target_da = (uint8_t)da;
				return 0;
			}
		}
	}
	return -EAGAIN;
}

static void *suite_setup(void)
{
	int rc;

	printk(">>> TD SUITE_SETUP ENTER\n");

	zassert_true(device_is_ready(i3c_dev), "I3C target %s not ready", i3c_dev->name);
	zassert_true(device_is_ready(sync_uart), "Sync UART %s not ready", sync_uart->name);

	sync_drain(sync_uart);

	rc = target_configure();
	zassert_ok(rc, "target configure/register failed (%d)", rc);

	rc = await_enumeration(K_SECONDS(60));
	if (rc != 0) {
		printk("*** no ENUM from Board A (%d) - bus tests will fail ***\n", rc);
	}
	printk("[setup] Board A reports our DA = 0x%02x\n", target_da);

	return NULL;
}

static void suite_before_each(void *fixture)
{
	ARG_UNUSED(fixture);

	/* A case that failed mid-transaction leaves bytes in flight; let
	 * the ISR finish before clearing, so they cannot be counted here.
	 */
	k_msleep(50);

	/* A case that zasserted between unregister and re-register leaves the
	 * wrong table bound, or none at all, which would fail every case after
	 * it for a reason that has nothing to do with them.
	 */
	zassert_ok(target_bind(&target_cfg), "could not restore the default callback table");

	event_reset();
}

ZTEST_SUITE(dual_board_loopback_target, NULL, suite_setup, suite_before_each, NULL, NULL);
```

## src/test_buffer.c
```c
/*
 * SPDX-FileCopyrightText: Copyright (c) 2026 Infineon Technologies AG,
 * SPDX-FileCopyrightText: or an affiliate of Infineon Technologies AG. All rights reserved.
 *
 * SPDX-License-Identifier: Apache-2.0
 *
 * Buffer-mode callback contract.
 *
 * Built only when CONFIG_I3C_TARGET_BUFFER_MODE is set: without it the two
 * callbacks are not even members of struct i3c_target_callbacks.
 *
 * These cases assert the contract in include/zephyr/drivers/i3c/target_device.h
 * rather than what any one driver happens to do, so a red case here is a work
 * item on the driver under test.
 */

#include "test_common.h"

#include <zephyr/drivers/i3c.h>
#include <zephyr/ztest.h>

#ifdef CONFIG_I3C_TARGET_BUFFER_MODE

/*
 * A private write arrives once, whole and in order.
 *
 * Source: target_device.h buf_write_received_cb, "invoked by the controller
 * when it completes reception of data from the source buffer to the
 * destination buffer in an ongoing write operation to the device".  One
 * completed write is therefore one callback carrying the whole payload,
 * which is what distinguishes this from the per-byte path in
 * test_write_payload_integrity.
 */
ZTEST(dual_board_loopback_target, test_buf_write_delivers_payload)
{
	uint8_t pattern[8];
	int wait_rc = -1;
	int a_rc = -1;
	int rc;

	I3C_DUAL_BOARD_LOOPBACK_REQUIRE_ENUMERATED();
	event_reset();
	target_buf_reset();

	fill_pattern(pattern, sizeof(pattern), 0x31);

	rc = target_buf_mode_enter();
	if (rc != 0) {
		(void)target_buf_mode_exit();
		zassert_ok(rc, "could not enter buffer mode (%d)", rc);
	}

	rc = ctrl_write(pattern, sizeof(pattern), &a_rc);
	if (rc == 0) {
		wait_rc = event_wait_count(EVENT_BUF_WRITE, 1U, CB_SETTLE);
	}

	(void)target_buf_mode_exit();

	zassert_ok(rc, "harness: no reply from Board A (%d)", rc);
	zassert_ok(a_rc, "Board A could not write (%d)", a_rc);
	zassert_ok(wait_rc, "buf_write_received_cb never fired for an %zu-byte write",
		   sizeof(pattern));

	zassert_equal(event_count(EVENT_BUF_WRITE), 1U,
		      "one write produced %zu buf callbacks, want exactly 1",
		      event_count(EVENT_BUF_WRITE));
	zassert_equal(target_buf_rx_len, sizeof(pattern), "callback reported %zu bytes, want %zu",
		      target_buf_rx_len, sizeof(pattern));
	zassert_mem_equal(target_buf_rx, pattern, sizeof(pattern),
			  "payload differs or is reordered");
}

/*
 * The reported length is exact at both edges.
 *
 * Source: target_device.h buf_write_received_cb @p len, "the length of the
 * data to be transferred".  A driver that rounded up to a FIFO word, padded,
 * or clamped short would pass test_buf_write_delivers_payload and fail here.
 * The scenario pins CONFIG_I3C_DW_TARGET_BUF_SIZE to TARGET_BUF_MAX so the
 * long case exactly fills the driver buffer; a write longer than the buffer
 * is a configuration error the driver logs, not a case this asserts.
 */
ZTEST(dual_board_loopback_target, test_buf_write_length_boundary)
{
	static const size_t lengths[] = {1U, TARGET_BUF_MAX};

	I3C_DUAL_BOARD_LOOPBACK_REQUIRE_ENUMERATED();

	for (size_t i = 0; i < ARRAY_SIZE(lengths); i++) {
		uint8_t pattern[TARGET_BUF_MAX];
		const size_t len = lengths[i];
		int wait_rc = -1;
		int a_rc = -1;
		int rc;

		event_reset();
		target_buf_reset();
		fill_pattern(pattern, len, (uint8_t)(0x40 + i));

		rc = target_buf_mode_enter();
		if (rc != 0) {
			(void)target_buf_mode_exit();
			zassert_ok(rc, "could not enter buffer mode (%d)", rc);
		}

		rc = ctrl_write(pattern, len, &a_rc);
		if (rc == 0) {
			wait_rc = event_wait_count(EVENT_BUF_WRITE, 1U, CB_SETTLE);
		}

		(void)target_buf_mode_exit();

		zassert_ok(rc, "harness: no reply from Board A (%d)", rc);
		zassert_ok(a_rc, "Board A could not write %zu bytes (%d)", len, a_rc);
		zassert_ok(wait_rc, "no buf callback for the %zu-byte write", len);

		zassert_equal(target_buf_rx_len, len, "callback reported %zu bytes, want %zu",
			      target_buf_rx_len, len);
		zassert_mem_equal(target_buf_rx, pattern, len, "%zu-byte payload differs", len);
	}
}

/*
 * A buffer staged for reading is returned whole, in order.
 *
 * Source: MIPI I3C Basic v1.0 5.1.2.3 plus target_device.h.  This asserts the
 * requirement, not the mechanism: buf_read_requested_cb cannot supply the data
 * for the transfer under way, because I3C forbids target clock stretching
 * (spec Table 10, "Clock Stretching by Slave" -- Not Allowed), so the target
 * must already hold the bytes when the data phase starts.  Read data is
 * therefore pre-staged with i3c_target_tx_write() in buffer mode exactly as it
 * is in byte mode, and the callback is only an underrun report
 * (test_buf_unstaged_read_is_reported).
 */
ZTEST(dual_board_loopback_target, test_buf_read_returns_staged_bytes)
{
	uint8_t staged[8];
	uint8_t got[TARGET_BUF_MAX];
	int a_rc = -1;
	int rc;

	I3C_DUAL_BOARD_LOOPBACK_REQUIRE_ENUMERATED();
	event_reset();
	target_buf_reset();

	fill_pattern(staged, sizeof(staged), 0x51);

	rc = target_buf_mode_enter();
	if (rc != 0) {
		(void)target_buf_mode_exit();
		zassert_ok(rc, "could not enter buffer mode (%d)", rc);
	}

	rc = target_stage_read(staged, sizeof(staged));
	if (rc == 0) {
		rc = ctrl_read(sizeof(staged), got, sizeof(got), &a_rc);
	}

	(void)target_buf_mode_exit();

	zassert_ok(rc, "harness: staging or reply failed (%d)", rc);
	zassert_ok(a_rc, "Board A could not read (%d)", a_rc);
	zassert_mem_equal(got, staged, sizeof(staged),
			  "buffer mode did not return the staged bytes intact");
}

/*
 * A read with nothing staged is reported, not served with stale bytes.
 *
 * Source: target_device.h buf_read_requested_cb, "invoked by the controller
 * when the bus is ready to provide additional data by buffer", read together
 * with DW databook 6.1.9 bit 11: the DW IP raises that event only when
 * the command queue is empty, so it is the underrun case and nothing more.
 * The documented "an error return shall cause the controller to ignore bus
 * operations" cannot be asserted here -- no in-tree I3C driver consumes the
 * return value, because by the time the event fires the transfer is already
 * lost.  What is left, and what this asserts, is that the application is told:
 * the bytes the controller ends up with are the IP's business, not the
 * driver's, so they are deliberately not asserted on.
 */
ZTEST(dual_board_loopback_target, test_buf_unstaged_read_is_reported)
{
	uint8_t got[TARGET_BUF_MAX];
	size_t notes;
	int a_rc = -1;
	int rc;

	I3C_DUAL_BOARD_LOOPBACK_REQUIRE_ENUMERATED();
	event_reset();
	target_buf_reset();

	rc = target_buf_mode_enter();
	if (rc != 0) {
		(void)target_buf_mode_exit();
		zassert_ok(rc, "could not enter buffer mode (%d)", rc);
	}

	/* Nothing staged on purpose. */
	rc = ctrl_read(4U, got, sizeof(got), &a_rc);
	notes = event_count(EVENT_BUF_READ);

	(void)target_buf_mode_exit();

	zassert_ok(rc, "harness: no reply from Board A (%d)", rc);
	zassert_true(notes > 0U,
		     "the underrun was not reported to the application: rc=%d, %zu reports", a_rc,
		     notes);
}

/*
 * Completion is still signalled exactly once, after the buf callback.
 *
 * Source: target_device.h stop_cb, "invoked when the bus completes a stop
 * condition".  Nothing in the API makes stop_cb conditional on the per-byte
 * path, so buffer mode must not swallow it, and the ordering is what proves
 * the buf callback belongs to the transaction the stop closes.
 */
ZTEST(dual_board_loopback_target, test_buf_stop_still_signalled)
{
	uint8_t pattern[8];
	size_t buf_idx = SIZE_MAX;
	size_t stop_idx = SIZE_MAX;
	int wait_rc = -1;
	int a_rc = -1;
	int rc;

	I3C_DUAL_BOARD_LOOPBACK_REQUIRE_ENUMERATED();
	event_reset();
	target_buf_reset();

	fill_pattern(pattern, sizeof(pattern), 0x71);

	rc = target_buf_mode_enter();
	if (rc != 0) {
		(void)target_buf_mode_exit();
		zassert_ok(rc, "could not enter buffer mode (%d)", rc);
	}

	rc = ctrl_write(pattern, sizeof(pattern), &a_rc);
	if (rc == 0) {
		wait_rc = event_wait_count(EVENT_STOP, 1U, CB_SETTLE);
	}

	(void)target_buf_mode_exit();

	zassert_ok(rc, "harness: no reply from Board A (%d)", rc);
	zassert_ok(a_rc, "Board A could not write (%d)", a_rc);
	zassert_ok(wait_rc, "stop_cb never fired in buffer mode");

	zassert_equal(event_count(EVENT_STOP), 1U, "one transaction produced %zu stops, want 1",
		      event_count(EVENT_STOP));

	for (size_t i = 0; i < event_stored(); i++) {
		const struct event_entry *ev = event_at(i);

		if ((ev->kind == EVENT_BUF_WRITE) && (buf_idx == SIZE_MAX)) {
			buf_idx = i;
		}
		if ((ev->kind == EVENT_STOP) && (stop_idx == SIZE_MAX)) {
			stop_idx = i;
		}
	}

	zassert_not_equal(buf_idx, SIZE_MAX, "no buf_write_received_cb before the stop");
	zassert_true(buf_idx < stop_idx, "stop_cb fired before the payload was delivered");
}

/*
 * A transfer is delivered by exactly one path, never both.
 *
 * Not a stated contract, but a rule every in-tree driver supporting both
 * modes enforces.  Worth pinning because in i3c_dw.c the exclusivity rests on
 * a single return after the buf callback rather than on #ifdef structure, so
 * a refactor could silently lose it.  No other buffer-mode case would notice:
 * they register a buf-only table, so the per-byte path cannot fire whatever
 * the driver does.
 *
 * Waiting on the stop rather than on the buf callback is what makes the
 * negative half sound: the per-byte callbacks run during the data phase that
 * precedes the stop, so once the stop is in the log both paths have already
 * had their chance to fire.
 */
ZTEST(dual_board_loopback_target, test_buf_path_excludes_byte_path)
{
	uint8_t pattern[8];
	size_t bytes;
	size_t bufs;
	int wait_rc = -1;
	int a_rc = -1;
	int rc;

	I3C_DUAL_BOARD_LOOPBACK_REQUIRE_ENUMERATED();
	event_reset();
	target_buf_reset();

	fill_pattern(pattern, sizeof(pattern), 0x81);

	rc = target_both_mode_enter();
	if (rc != 0) {
		(void)target_both_mode_exit();
		zassert_ok(rc, "could not register both callback paths (%d)", rc);
	}

	rc = ctrl_write(pattern, sizeof(pattern), &a_rc);
	if (rc == 0) {
		wait_rc = event_wait_count(EVENT_STOP, 1U, CB_SETTLE);
	}

	bytes = event_count(EVENT_WRITE_BYTE);
	bufs = event_count(EVENT_BUF_WRITE);

	(void)target_both_mode_exit();

	zassert_ok(rc, "harness: no reply from Board A (%d)", rc);
	zassert_ok(a_rc, "Board A could not write (%d)", a_rc);
	zassert_ok(wait_rc, "the transaction never completed, so neither path was observed");

	zassert_equal(bufs, 1U, "buffer path delivered the write %zu times, want exactly 1", bufs);
	zassert_equal(bytes, 0U,
		      "the write was double-handled: %zu per-byte callbacks alongside the "
		      "buffer callback, for one %zu-byte transfer",
		      bytes, sizeof(pattern));

	zassert_equal(target_buf_rx_len, sizeof(pattern), "callback reported %zu bytes, want %zu",
		      target_buf_rx_len, sizeof(pattern));
	zassert_mem_equal(target_buf_rx, pattern, sizeof(pattern),
			  "the surviving path did not deliver the payload intact");
}

#endif /* CONFIG_I3C_TARGET_BUFFER_MODE */
```
